# GD32H7xx register map
File version: 1.0
CPU: CM7 r1p2, little endian, MPU, FPU, 4 interrupt priority bits
Registers are 32-bit, read-write, reset 0x0 unless marked. A register's access mark holds for its fields unless they carry their own. Offsets are from the block's base; [hi:lo] are bit positions; {n}, {i} and the like mark numbered series.

## DCI — Digital Camera Interface
Base 0x48020000
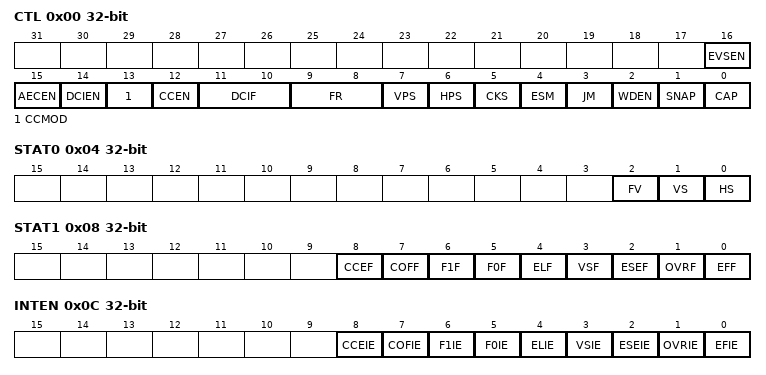
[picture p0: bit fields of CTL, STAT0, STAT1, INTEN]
0x00 CTL — Control register
  [16] EVSEN — External vsync enable
  [15] AECEN — Automatic error correction enable
  [14] DCIEN — DCI Enable
  [13] CCMOD — CCIR mode select
  [12] CCEN — CCIR enable
  [11:10] DCIF — Digital camera interface format
  [9:8] FR — Frame rate
  [7] VPS — Vertical Polarity Selection
  [6] HPS — Horizontal Polarity Selection
  [5] CKS — Clock Polarity Selection
  [4] ESM — Embedded Synchronous Mode
  [3] JM — JPEG mode
  [2] WDEN — Window Enable
  [1] SNAP — Snapshot mode
  [0] CAP — Capture Enable
0x04 STAT0 ro — Status register 0
  [2] FV — FIFO Valid
  [1] VS — VS line status
  [0] HS — HS line status
0x08 STAT1 ro — Status register 1
  [8] CCEF — CCIR error flag
  [7] COFF — CCIR change of field flag
  [6] F1F — CCIR field 1
  [5] F0F — CCIR field 0
  [4] ELF — End of Line Flag
  [3] VSF — Vsync Flag
  [2] ESEF — Embedded Synchronous Error Flag
  [1] OVRF — FIFO Overrun Flag
  [0] EFF — End of Frame Flag
0x0C INTEN — Interrupt enable register
  [8] CCEIE — CCIR error Interrupt enable
  [7] COFIE — CCIR change of field interrupt enable
  [6] F1IE — CCIR field 1 interrupt enable
  [5] F0IE — CCIR field 0 interrupt enable
  [4] ELIE — End of Line Interrupt Enable
  [3] VSIE — Vsync Interrupt Enable
  [2] ESEIE — Embedded Synchronous Error Interrupt Enable
  [1] OVRIE — FIFO Overrun Interrupt Enable
  [0] EFIE — End of Frame Interrupt Enable
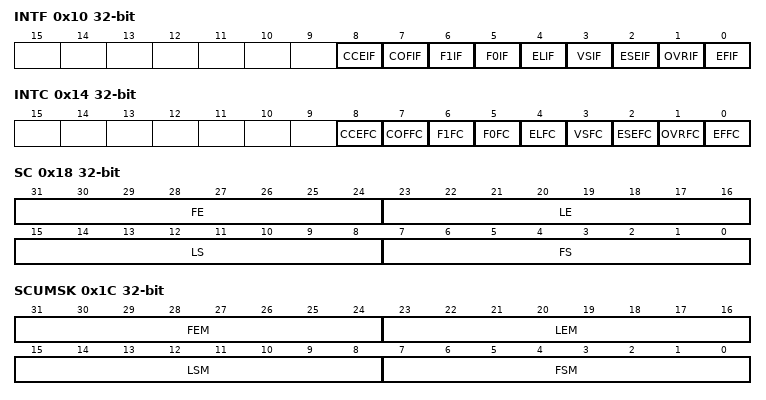
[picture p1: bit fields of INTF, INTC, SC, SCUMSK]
0x10 INTF ro — Interrupt flag register
  [8] CCEIF — CCIR error interrupt flag
  [7] COFIF — CCIR change of field interrupt flag
  [6] F1IF — CCIR field 1 interrupt flag
  [5] F0IF — CCIR field 0 interrupt flag
  [4] ELIF — End of Line Interrupt Flag
  [3] VSIF — Vsync Interrupt Flag
  [2] ESEIF — Embedded Synchronous Error Interrupt Flag
  [1] OVRIF — FIFO Overrun Interrupt Flag
  [0] EFIF — End of Frame Interrupt Flag
0x14 INTC wo — Interrupt flag clear register
  [8] CCEFC — CCIR error flag clear
  [7] COFFC — CCIR change of field flag clear
  [6] F1FC — CCIR field 1 interrupt flag clear
  [5] F0FC — CCIR field 0 interrupt flag clear
  [4] ELFC — End of Line Flag Clear
  [3] VSFC — Vsync flag clear
  [2] ESEFC — Clear embedded synchronous Error Flag
  [1] OVRFC — Clear FIFO Overrun Flag
  [0] EFFC — Clear End of Frame Flag
0x18 SC — Synchronization codes register
  [31:24] FE — Frame End Code in Embedded Synchronous Mode
  [23:16] LE — Line End Code in Embedded Synchronous Mode
  [15:8] LS — Line Start Code in Embedded Synchronous Mode
  [7:0] FS — Frame Start Code in Embedded Synchronous Mode
0x1C SCUMSK — Synchronization codes unmask register
  [31:24] FEM — Frame End Code unMask Bits in Embedded Synchronous Mode
  [23:16] LEM — Line End Code unMask Bits in Embedded Synchronous Mode
  [15:8] LSM — Line Start Code unMask Bits in Embedded Synchronous Mode
  [7:0] FSM — Frame Start Code unMask Bits in Embedded Synchronous Mode
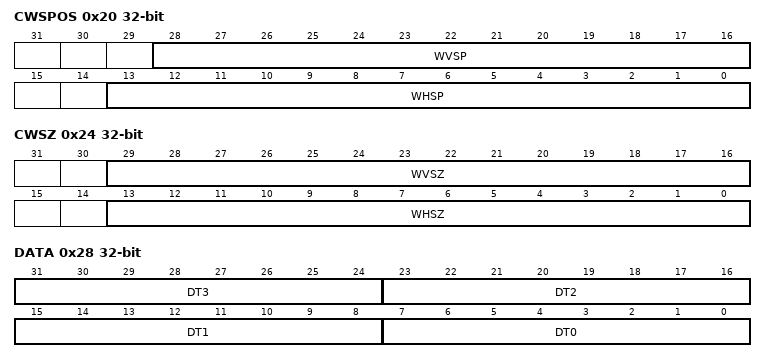
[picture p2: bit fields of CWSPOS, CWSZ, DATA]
0x20 CWSPOS — Cropping window start position register
  [28:16] WVSP — Window Vertical Start Position
  [13:0] WHSP — Window Horizontal Start Position
0x24 CWSZ — Cropping window size register
  [29:16] WVSZ — Window Vertical Size
  [13:0] WHSZ — Window Horizontal Size
0x28 DATA ro
  [8n+7:8n] DT{n} (n=0..3) — Pixel Data {n}

## DAC — Digital-to-analog converter
Base 0x40007400
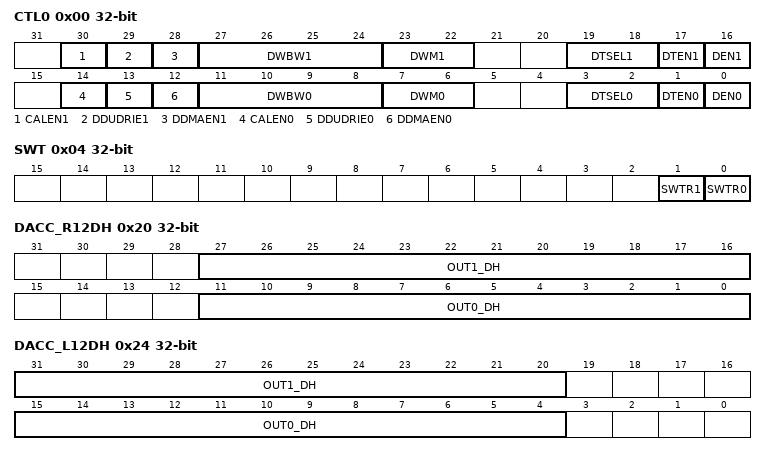
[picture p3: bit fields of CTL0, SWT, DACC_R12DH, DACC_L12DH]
0x00 CTL0 — Control register 0
  [30] CALEN1 — DAC_OUT1 calibration enable
  [29] DDUDRIE1 — DAC_OUT1 DMA underrun interrupt enable
  [28] DDMAEN1 — DAC_OUT1 DMA enable
  [27:24] DWBW1 — DAC_OUT1 noise wave bit width
  [23:22] DWM1 — DAC_OUT1 noise wave mode
  [19:18] DTSEL1 — DAC_OUT1 trigger selection
  [17] DTEN1 — DAC_OUT1 trigger enable
  [16] DEN1 — DAC_OUT1 enable
  [14] CALEN0 — DAC_OUT0 calibration enable
  [13] DDUDRIE0 — DAC_OUT0 DMA underrun interrupt enable
  [12] DDMAEN0 — DAC_OUT0 DMA enable
  [11:8] DWBW0 — DAC_OUT0 noise wave bit width
  [7:6] DWM0 — DAC_OUT0 noise wave mode
  [3:2] DTSEL0 — DAC_OUT0 trigger selection
  [1] DTEN0 — DAC_OUT0 trigger enable
  [0] DEN0 — DAC_OUT0 enable
0x04 SWT wo — Software trigger register
  [1] SWTR1 — DAC_OUT1 software trigger, cleared by hardware
  [0] SWTR0 — DAC_OUT0 software trigger, cleared by hardware
0x08 OUT0_R12DH — DAC_OUT0 12-bit right-aligned data holding register
  [11:0] OUT0_DH — DAC_OUT0 12-bit right-aligned data
0x0C OUT0_L12DH — DAC_OUT0 12-bit left-aligned data holding register
  [15:4] OUT0_DH — DAC_OUT0 12-bit left-aligned data
0x10 OUT0_R8DH — DAC_OUT0 8-bit right-aligned data holding register
  [7:0] OUT0_DH — DAC_OUT0 8-bit right-aligned data
0x14 OUT1_R12DH — DAC_OUT1 12-bit right-aligned data holding register
  [11:0] OUT1_DH — DAC_OUT1 12-bit right-aligned data
0x18 OUT1_L12DH — DAC_OUT1 12-bit left-aligned data holding register
  [15:4] OUT1_DH — OUT1_DH[11:0]
0x1C OUT1_R8DH — DAC_OUT1 8-bit right-aligned data holding register
  [7:0] OUT1_DH — DAC_OUT1 8-bit right-aligned data
0x20 DACC_R12DH — DAC concurrent mode 12-bit right-aligned data holding register
  [27:16] OUT1_DH — DAC_OUT1 12-bit right-aligned data
  [11:0] OUT0_DH — DAC_OUT0 12-bit right-aligned data
0x24 DACC_L12DH — DAC concurrent mode 12-bit left-aligned data holding register
  [31:20] OUT1_DH — DAC_OUT1 12-bit left-aligned data
  [15:4] OUT0_DH — DAC_OUT0 12-bit left-aligned data
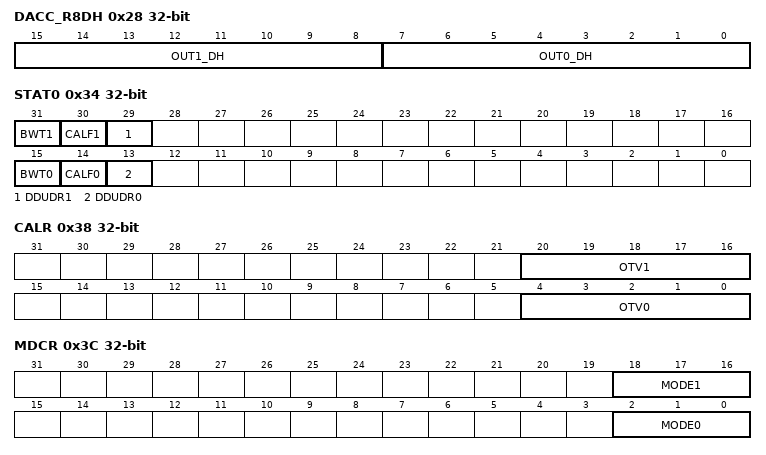
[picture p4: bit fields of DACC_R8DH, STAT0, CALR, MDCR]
0x28 DACC_R8DH — DAC concurrent mode 8-bit right-aligned data holding register
  [15:8] OUT1_DH — DAC_OUT1 8-bit right-aligned data
  [7:0] OUT0_DH — DAC_OUT0 8-bit right-aligned data
0x2C OUT0_DO ro — DAC_OUT0 data output register
  [11:0] OUT0_DO — DAC_OUT0 data output
0x30 OUT1_DO ro — DAC_OUT1 data output register
  [11:0] OUT1_DO — DAC_OUT1 data output
0x34 STAT0 ro — DAC Status register 0
  [31] BWT1 — This bit will be set after sample and keep mode enable
  [30] CALF1 — DAC_OUT1 calibration offset flag
  [29] DDUDR1 — DAC_OUT1 DMA underrun flag, set by hardware, cleared by software write 1
  [15] BWT0 — This bit will be set after sample and keep mode enable
  [14] CALF0 — DAC_OUT0 calibration offset flag
  [13] DDUDR0 — DAC_OUT0 DMA underrun flag, set by hardware, cleared by software write 1
0x38 CALR — DAC calibration Register 1
  [20:16] OTV1 — DAC_OUT1 offset calibration value
  [4:0] OTV0 — DAC_OUT0 offset calibration value
0x3C MDCR — DAC mode control Register 1
  [18:16] MODE1 — DAC OUT1 mode.
  [2:0] MODE0 — DAC OUT0 mode.
0x40 SKSTR0 — DAC sample and keep sample time Register 0
  [9:0] TSAMP0 — DAC_OUT0 sample time.
0x44 SKSTR1 — DAC sample and keep sample time Register 1
  [9:0] TSAMP1 — DAC_OUT refresh time (only valid in Sample and hold mode)
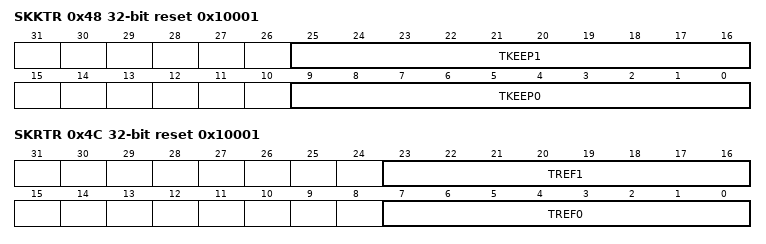
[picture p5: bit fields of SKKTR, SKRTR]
0x48 SKKTR reset 0x10001 — DAC sample and keep keep time Register
  [25:16] TKEEP1 — DAC_OUT1 keep time
  [9:0] TKEEP0 — DAC_OUT0 keep time
0x4C SKRTR reset 0x10001 — DAC sample and keep refresh time Register
  [23:16] TREF1 — DAC_OUT1 refresh time
  [7:0] TREF0 — DAC_OUT0 refresh time
